# S32K322_M7 register map
Vendor: NXP Semiconductors; File version: 1.0
CPU: CM7 r0p1, little endian, MPU, FPU, VTOR, 4 interrupt priority bits
Registers are 32-bit, read-write, reset 0x0 unless marked. A register's access mark holds for its fields unless they carry their own. Offsets are from the block's base; [hi:lo] are bit positions; {n}, {i} and the like mark numbered series.

## FCCU
Base 0x40384000
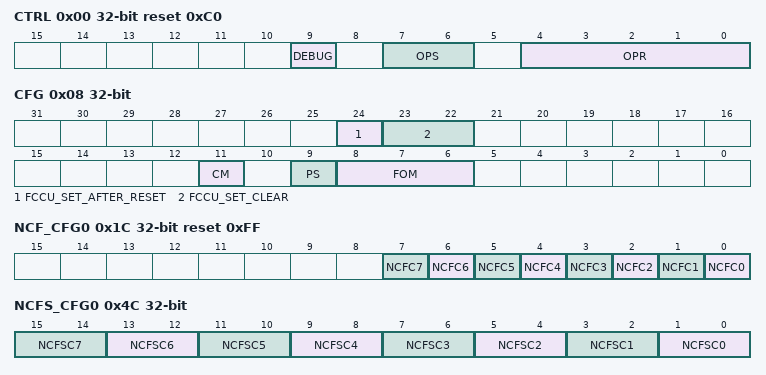
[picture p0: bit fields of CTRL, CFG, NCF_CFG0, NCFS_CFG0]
0x00 CTRL reset 0xC0 — Control
  [9] DEBUG — Debug Mode Enable
    0=id0 (Disabled); 1=id1 (Enabled)
  [7:6] OPS ro — Operation Status
    0=id0 (Idle); 1=id01 (In progress); 2=id10 (Aborted); 3=id11 (Successful)
  [4:0] OPR — Operation Run
0x04 CTRLK wo — Control Key
  [31:0] CTRLK — Locked-Operation Control Key
0x08 CFG — Configuration
  [24] FCCU_SET_AFTER_RESET — Fault-Output (EOUT) Activate
    0=id0 (Inactive (the EOUT signals are in a high-impedance state)); 1=id1 (Active (the EOUT signals indicate FCCU's condition))
  [23:22] FCCU_SET_CLEAR — Fault-Output (EOUT) Control
    0=id00 (Controlled by the FSM); 1=id01 (Always low); 2=id10 (Controlled by the FSM); 3=id11 (High until a fault occurs on a channel, regardless of whether that fault is disabled; thereafter, controlled by the FSM. Note: FCCU ignores an attempt to write this value if the fault-output (EOUT) timer is already running.)
  [11] CM — Fault-Output (EOUT) Configuration-Indication Mode
    0=id0 (Different); 1=id1 (Same)
  [9] PS — Fault-Output (EOUT) Polarity Selection
    0=id0 (For the faulty indication, EOUT1 is high, and EOUT0 is low.); 1=id1 (For the faulty indication, EOUT1 is low, and EOUT0 is high.)
  [8:6] FOM — Fault-Output (EOUT) Mode
    2=id010 (Bi-Stable); 5=id101 (Test 0 (controlled by the EINOUT register; EOUT1 is an output; EOUT0 is an input)); 6=id110 (Test 1 (controlled by the EINOUT register; EOUT1 and EOUT0 are both outputs)); 7=id (Test 2 (controlled by the EINOUT register; EOUT1 is an input; EOUT0 is an output))
0x1C NCF_CFG0 reset 0xFF — Non-critical Fault Configuration
  [all] fields
    0=id0 (Hardware-recoverable); 1=id1 (Software-recoverable)
  [n] NCFC{n} (n=0..7) — Non-critical Fault Configuration n
0x4C NCFS_CFG0 — Non-critical Fault-State Configuration
  [all] fields
    0=id00 (Disabled); 1=id01 (Enabled (rst_sfunc_b) (short)); 3=id11 (Disabled)
  [2n+1:2n] NCFSC{n} (n=0..7) — Non-critical Fault-State Configuration n
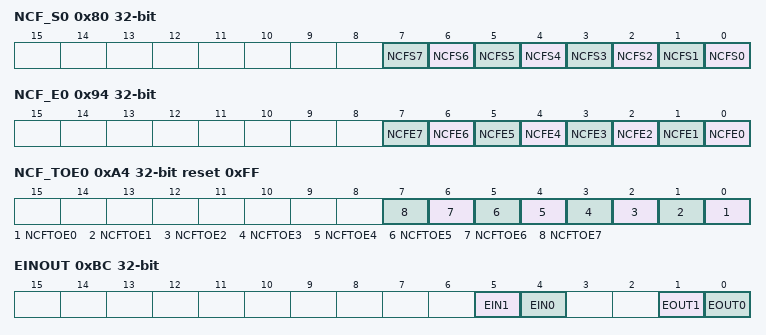
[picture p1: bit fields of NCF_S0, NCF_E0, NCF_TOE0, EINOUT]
0x80 NCF_S0 write-1-clears — Non-critical Fault Status
  [all] fields
    0=id0 (No unrecovered fault); 1=id1 (Unrecovered fault)
  [n] NCFS{n} write-1-clears (n=0..7) — Non-critical Fault Status n
0x90 NCFK — Non-critical Fault Key
0x94 NCF_E0 — Non-critical Fault Enable
  [all] fields
    0=id0 (Disabled); 1=id1 (Enabled)
  [n] NCFE{n} (n=0..7) — Non-critical Fault Enable n
0xA4 NCF_TOE0 reset 0xFF — Non-critical-Fault Alarm-State Timeout Enable
  [all] fields
    0=id0 (Disabled); 1=id1 (Enabled)
  [n] NCFTOE{n} (n=0..7) — Non-critical-Fault Alarm-State Timeout Enable n
0xB4 NCF_TO reset 0x3A980 — Non-critical-Fault Alarm-State Timeout Interval
0xB8 CFG_TO reset 0x5 — Configuration-State Timeout Interval
  [2:0] TO
0xBC EINOUT (reset mask 0xFFFFFFCF) — IO Control
  [5] EIN1 ro — Error Input 1
    0=id0 (Low); 1=id1 (High)
  [4] EIN0 ro — Error Input 0
    0=id0 (Low); 1=id1 (High)
  [1] EOUT1
    0=id0 (force EOUT[1] = 0); 1=id1 (force EOUT[1] = 1)
  [0] EOUT0
    0=id0 (force EOUT[0] = 0); 1=id1 (force EOUT[0] = 1)
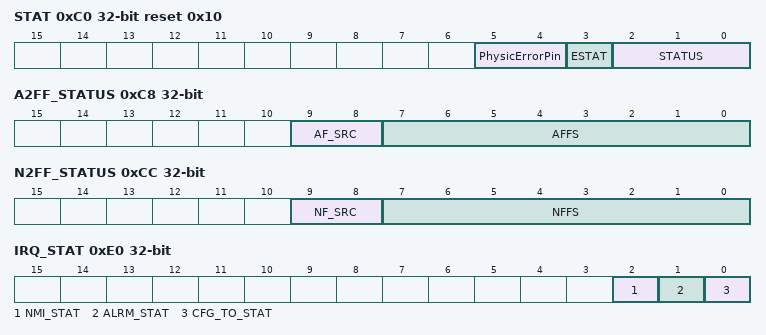
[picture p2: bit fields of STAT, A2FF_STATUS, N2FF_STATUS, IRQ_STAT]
0xC0 STAT ro reset 0x10 — Status
  [5:4] PhysicErrorPin — EOUT Signal States
    0=id00 (EOUT1 is low; EOUT0 is low.); 1=id01 (EOUT1 is low; EOUT0 is high.); 2=id10 (EOUT1 is high; EOUT0 is low.); 3=id11 (EOUT1 is high; EOUT0 is high.)
  [3] ESTAT — FCCU Faulty Condition
    0=id0 (Not in faulty condition (in nonfaulty or configuration condition)); 1=id1 (In faulty condition)
  [2:0] STATUS — FCCU State
    0=id000 (NORMAL); 1=id001 (CONFIG); 2=id010 (ALARM); 3=id011 (FAULT)
0xC4 N2AF_STATUS ro — Normal-to-Alarm Freeze Status
  [7:0] NAFS
0xC8 A2FF_STATUS ro — Alarm-to-Fault Freeze Status
  [9:8] AF_SRC — Alarm-to-Fault Source
    0=id00 (No Alarm-to-Fault-state fault); 2=id10 (Non-critical fault); 3=id11 (Multiple Alarm-to-Fault-state faults)
  [7:0] AFFS — Alarm-to-Fault Freeze Status
0xCC N2FF_STATUS ro — Normal-to-Fault Freeze Status
  [9:8] NF_SRC — Normal-to-Fault Source
    0=id00 (No Normal-to-Fault-state fault); 2=id10 (Non-critical fault); 3=id11 (Multiple Normal-to-Fault-state faults)
  [7:0] NFFS — Normal-to-Fault Freeze Status
0xD0 F2AF_STATUS ro — Fault-to-Alarm Freeze Status
  [8:0] FAFS
0xDC NCFF wo — Non-critical Fault Fake
  [6:0] FNCFC
0xE0 IRQ_STAT — IRQ Status
  [2] NMI_STAT ro — NMI Interrupt Status
    0=id0 (NMI interrupt is OFF); 1=id1 (NMI interrupt is ON)
  [1] ALRM_STAT ro — Alarm Interrupt Status
    0=id0 (Alarm interrupt is OFF); 1=id1 (Alarm interrupt is ON)
  [0] CFG_TO_STAT write-1-clears — Configuration-State Timeout Status
    0=id0 (No configuration-stat timeout error); 1=id1 (Configuration-state timeout error)
0xE4 IRQ_EN — IRQ Enable
  [0] CFG_TO_IEN — Configuration-State Timeout Interrupt Enable
    0=id0 (Configuration-state timeout interrupt disabled); 1=id1 (Configuration-state timeout interrupt enabled)
0xF0 TRANS_LOCK wo — Transient Configuration Lock
  [8:0] TRANSKEY
0xF4 PERMNT_LOCK wo — Permanent Configuration Lock
  [8:0] PERMNTKEY
0xF8 DELTA_T
  [13:0] DELTA_T — Minimum Fault-Output (EOUT) Timer Interval
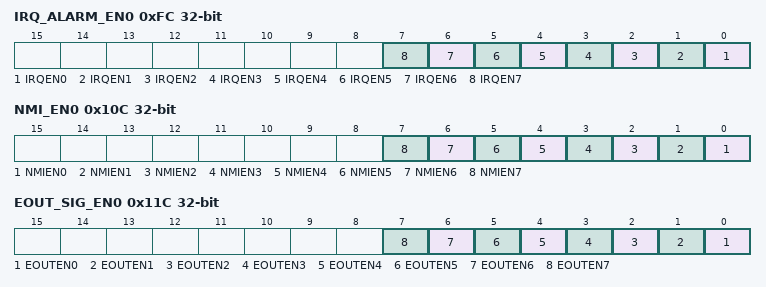
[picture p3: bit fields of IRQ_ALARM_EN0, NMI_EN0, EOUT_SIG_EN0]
0xFC IRQ_ALARM_EN0 — Non-critical Alarm-State Interrupt-Request Enable
  [all] fields
    0=id0 (Disabled); 1=id1 (Enabled)
  [n] IRQEN{n} (n=0..7) — Non-critical Alarm-State Interrupt-Request Enable n
0x10C NMI_EN0 — Non-critical Fault-State Non-maskable-Interrupt-Request Enable
  [all] fields
    0=id0 (Disabled); 1=id1 (Enabled)
  [n] NMIEN{n} (n=0..7) — Non-critical Fault-State Non-maskable-Interrupt-Request Enable n
0x11C EOUT_SIG_EN0 — Non-critical Fault-State EOUT Signaling Enable
  [all] fields
    0=id0 (In Bi-Stable fault-output mode, both EOUT signaling and FIF assertion are disabled; in other fault-output modes, EOUT signaling is enabled and FIF assertion is disabled.); 1=id1 (Both EOUT signaling and FIF assertion are enabled in all fault-output modes.)
  [n] EOUTEN{n} (n=0..7) — Non-critical Fault-State EOUT Signaling Enable n
0x12C TMR_ALARM ro reset 0x3A980 — Alarm-State Timer
  [31:0] COUNT — Alarm-State Timer Count
0x134 TMR_CFG ro reset 0xFFFFF — Configuration-State Timer
  [31:0] COUNT — Configuration-State Timer Count
0x138 TMR_ETMR ro — Fault-Output Timer
  [31:0] COUNT — Fault-Output Timer Count
